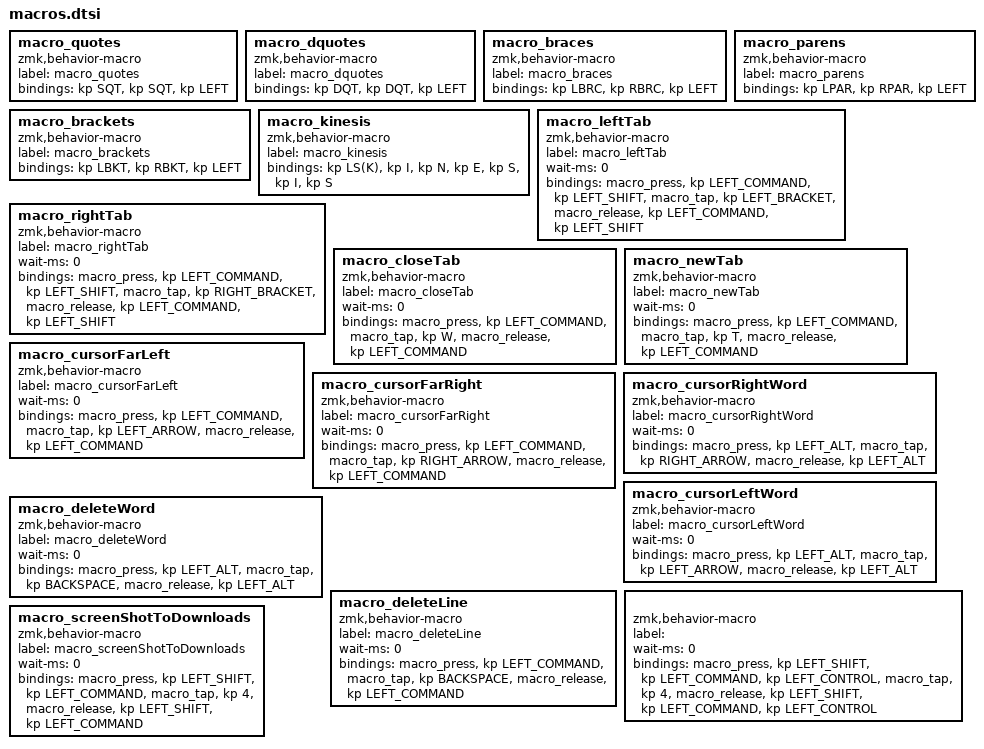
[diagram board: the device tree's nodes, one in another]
  macro_quotes: macro_quotes {
    compatible = "zmk,behavior-macro";
    label = "macro_quotes";
    #binding-cells = <0>;
    bindings = <&kp SQT>, <&kp SQT>, <&kp LEFT>;
  };
  macro_dquotes: macro_dquotes {
    compatible = "zmk,behavior-macro";
    label = "macro_dquotes";
    #binding-cells = <0>;
    bindings = <&kp DQT>, <&kp DQT>, <&kp LEFT>;
  };
  macro_braces: macro_braces {
    compatible = "zmk,behavior-macro";
    label = "macro_braces";
    #binding-cells = <0>;
    bindings = <&kp LBRC>, <&kp RBRC>, <&kp LEFT>;
  };
  macro_parens: macro_parens {
    compatible = "zmk,behavior-macro";
    label = "macro_parens";
    #binding-cells = <0>;
    bindings = <&kp LPAR>, <&kp RPAR>, <&kp LEFT>;
  };
  macro_brackets: macro_brackets {
    compatible = "zmk,behavior-macro";
    label = "macro_brackets";
    #binding-cells = <0>;
    bindings = <&kp LBKT>, <&kp RBKT>, <&kp LEFT>;
  };
  macro_kinesis: macro_kinesis {
    compatible = "zmk,behavior-macro";
    label = "macro_kinesis";
    #binding-cells = <0>;
    bindings = <&kp LS(K)>, <&kp I>, <&kp N>, <&kp E>, <&kp S>, <&kp I>, <&kp S>;
  };
  macro_leftTab: macro_leftTab {
    compatible = "zmk,behavior-macro";
    label = "macro_leftTab";
    #binding-cells = <0>;
    wait-ms = <0>;
    bindings = <&macro_press &kp LEFT_COMMAND &kp LEFT_SHIFT>
               , <&macro_tap &kp LEFT_BRACKET>
               , <&macro_release &kp LEFT_COMMAND &kp LEFT_SHIFT>;
  };
  macro_rightTab: macro_rightTab {
    compatible = "zmk,behavior-macro";
    label = "macro_rightTab";
    #binding-cells = <0>;
    wait-ms = <0>;
    bindings = <&macro_press &kp LEFT_COMMAND &kp LEFT_SHIFT>
               , <&macro_tap &kp RIGHT_BRACKET>
               , <&macro_release &kp LEFT_COMMAND &kp LEFT_SHIFT>;
  };
  macro_closeTab: macro_closeTab {
    compatible = "zmk,behavior-macro";
    label = "macro_closeTab";
    #binding-cells = <0>;
    wait-ms = <0>;
    bindings = <&macro_press &kp LEFT_COMMAND>
               , <&macro_tap &kp W>
               , <&macro_release &kp LEFT_COMMAND>;
  };
  macro_newTab: macro_newTab {
    compatible = "zmk,behavior-macro";
    label = "macro_newTab";
    #binding-cells = <0>;
    wait-ms = <0>;
    bindings = <&macro_press &kp LEFT_COMMAND>
               , <&macro_tap &kp T>
               , <&macro_release &kp LEFT_COMMAND>;
  };
  macro_cursorFarLeft: macro_cursorFarLeft {
    compatible = "zmk,behavior-macro";
    label = "macro_cursorFarLeft";
    #binding-cells = <0>;
    wait-ms = <0>;
    bindings = <&macro_press &kp LEFT_COMMAND>
               , <&macro_tap &kp LEFT_ARROW>
               , <&macro_release &kp LEFT_COMMAND>;
  };
  macro_cursorFarRight: macro_cursorFarRight {
    compatible = "zmk,behavior-macro";
    label = "macro_cursorFarRight";
    #binding-cells = <0>;
    wait-ms = <0>;
    bindings = <&macro_press &kp LEFT_COMMAND>
               , <&macro_tap &kp RIGHT_ARROW>
               , <&macro_release &kp LEFT_COMMAND>;
  };
  macro_cursorRightWord: macro_cursorRightWord {
    compatible = "zmk,behavior-macro";
    label = "macro_cursorRightWord";
    #binding-cells = <0>;
    wait-ms = <0>;
    bindings = <&macro_press &kp LEFT_ALT>
               , <&macro_tap &kp RIGHT_ARROW>
               , <&macro_release &kp LEFT_ALT>;
  };
  macro_cursorLeftWord: macro_cursorLeftWord {
    compatible = "zmk,behavior-macro";
    label = "macro_cursorLeftWord";
    #binding-cells = <0>;
    wait-ms = <0>;
    bindings = <&macro_press &kp LEFT_ALT>
               , <&macro_tap &kp LEFT_ARROW>
               , <&macro_release &kp LEFT_ALT>;
  };
  macro_deleteWord: macro_deleteWord {
    compatible = "zmk,behavior-macro";
    label = "macro_deleteWord";
    #binding-cells = <0>;
    wait-ms = <0>;
    bindings = <&macro_press &kp LEFT_ALT>
               , <&macro_tap &kp BACKSPACE>
               , <&macro_release &kp LEFT_ALT>;
  };
  macro_deleteLine: macro_deleteLine {
    compatible = "zmk,behavior-macro";
    label = "macro_deleteLine";
    #binding-cells = <0>;
    wait-ms = <0>;
    bindings = <&macro_press &kp LEFT_COMMAND>
               , <&macro_tap &kp BACKSPACE>
               , <&macro_release &kp LEFT_COMMAND>;
  };
  :  {
    compatible = "zmk,behavior-macro";
    label = "";
    #binding-cells = <0>;
    wait-ms = <0>;
    bindings = <&macro_press &kp LEFT_SHIFT &kp LEFT_COMMAND &kp LEFT_CONTROL>
               , <&macro_tap &kp 4>
               , <&macro_release &kp LEFT_SHIFT &kp LEFT_COMMAND &kp LEFT_CONTROL>;
  };
  macro_screenShotToDownloads: macro_screenShotToDownloads {
    compatible = "zmk,behavior-macro";
    label = "macro_screenShotToDownloads";
    #binding-cells = <0>;
    wait-ms = <0>;
    bindings = <&macro_press &kp LEFT_SHIFT &kp LEFT_COMMAND>
               , <&macro_tap &kp 4>
               , <&macro_release &kp LEFT_SHIFT &kp LEFT_COMMAND>;
  };
